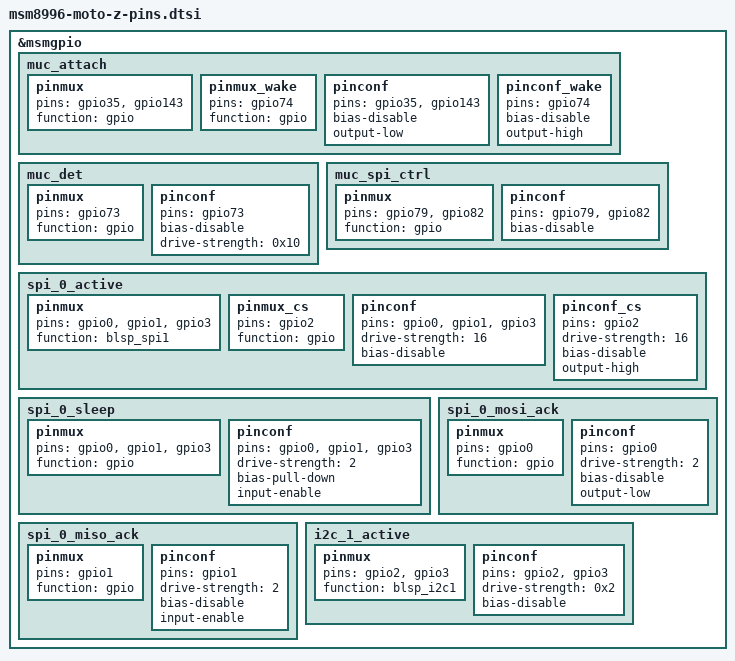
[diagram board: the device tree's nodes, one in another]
/*
 * Copyright (c) 2013-2015, The Linux Foundation. All rights reserved.
 *
 * This program is free software; you can redistribute it and/or modify
 * it under the terms of the GNU General Public License version 2 and
 * only version 2 as published by the Free Software Foundation.
 *
 * This program is distributed in the hope that it will be useful,
 * but WITHOUT ANY WARRANTY; without even the implied warranty of
 * MERCHANTABILITY or FITNESS FOR A PARTICULAR PURPOSE.  See the
 * GNU General Public License for more details.
 */

&msmgpio {
	muc_attach: muc_attach {
		pinmux {
			pins = "gpio35", "gpio143";
			function = "gpio";
		};

		pinmux_wake {
			pins = "gpio74";
			function = "gpio";
		};

		pinconf {
			pins = "gpio35", "gpio143";
			bias-disable;
			output-low;
		};

		pinconf_wake {
			pins = "gpio74";
			bias-disable;
			output-high;
		};
	};

	muc_det: muc_det {
		pinmux {
			pins = "gpio73";
			function = "gpio";
		};

		pinconf {
			pins = "gpio73";
			bias-disable;
			drive-strength = <0x10>;
		};
	};

	muc_spi_ctrl: muc_spi_ctrl {
		pinmux {
			pins = "gpio79", "gpio82";
			function = "gpio";
		};

		pinconf {
			pins = "gpio79", "gpio82";
			bias-disable;
		};
	};

	spi_0_active: spi_0_active {
		pinmux {
			pins = "gpio0", "gpio1", "gpio3";
			function = "blsp_spi1";
		};

		pinmux_cs {
			pins = "gpio2";
			function = "gpio";
		};

		pinconf {
			pins = "gpio0", "gpio1", "gpio3";
			drive-strength = <16>;
			bias-disable;
		};

		pinconf_cs {
			pins = "gpio2";
			drive-strength = <16>;
			bias-disable;
			output-high;
		};
	};

	spi_0_sleep: spi_0_sleep {
		pinmux {
			pins = "gpio0", "gpio1", "gpio3";
			function = "gpio";
		};

		pinconf {
			pins = "gpio0", "gpio1", "gpio3";
			drive-strength = <2>;
			bias-pull-down;
			input-enable;
		};
	};

	spi_0_mosi_ack: spi_0_mosi_ack {
		pinmux {
			pins = "gpio0";
			function = "gpio";
		};

		pinconf {
			pins = "gpio0";
			drive-strength = <2>;
			bias-disable;
			output-low;
		};
	};

	spi_0_miso_ack: spi_0_miso_ack {
		pinmux {
			pins = "gpio1";
			function = "gpio";
		};

		pinconf {
			pins = "gpio1";
			drive-strength = <2>;
			bias-disable;
			input-enable;
		};
	};

	i2c_1_active: i2c_1_active {
		pinmux {
			pins = "gpio2", "gpio3";
			function = "blsp_i2c1";
		};

		pinconf {
			pins = "gpio2", "gpio3";
			drive-strength = <0x2>;
			bias-disable;
		};
	};
};
